# XHSC_HC32F175 register map
Vendor: XHSC Co.Ltd; Series: ARMCM0P; File version: 1.0
CPU: CM0P r0p0, little endian, no MPU, no FPU, 3 interrupt priority bits
Registers are 32-bit, read-write, reset 0x0 unless marked. A register's access mark holds for its fields unless they carry their own. Offsets are from the block's base; [hi:lo] are bit positions; 'fields as' and 'values as' point back to an identical list.

## I2C0 — desc I2C
Base 0x40004800
Same registers: I2C1 0x40009000
0x00 BRREN
  [0] EN
0x04 BRR
  [7:0] BBR
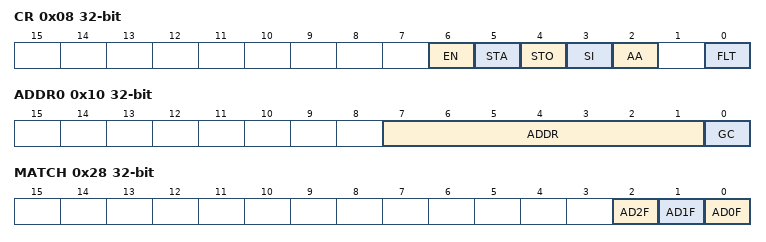
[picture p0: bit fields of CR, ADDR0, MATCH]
0x08 CR
  [6] EN, [5] STA, [4] STO, [3] SI, [2] AA, [0] FLT
0x0C DR
  [7:0] DR
0x10 ADDR0
  [7:1] ADDR, [0] GC
0x14 STAT ro reset 0xF8
  [7:0] STAT
0x20 ADDR1
  [7:0] ADDR
0x24 ADDR2
  [7:0] ADDR
0x28 MATCH ro
  [2] AD2F, [1] AD1F, [0] AD0F

## IWDT
Base 0x40000800
0x80 KR wo
  [15:0] KR rw
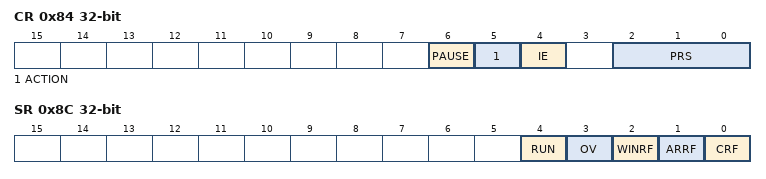
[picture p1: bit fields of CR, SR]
0x84 CR
  [6] PAUSE, [5] ACTION, [4] IE, [2:0] PRS
0x88 ARR reset 0xFFF
  [11:0] ARR
0x8C SR
  [4] RUN ro, [3] OV, [2] WINRF ro, [1] ARRF ro, [0] CRF ro
0x90 WINR reset 0xFFF
  [11:0] WINR

## LPTIM0 — desc LPTIM
Base 0x40005000
Same registers: LPTIM1 0x4000C000
0x00 CNT ro
  [15:0] CNT
0x04 ARR
  [15:0] ARR
0x08 CMP
  [15:0] CMP
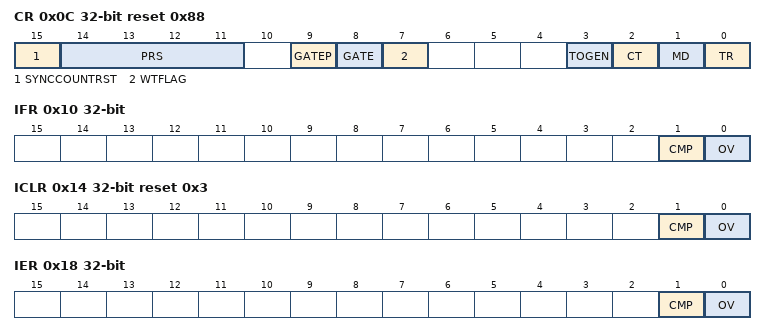
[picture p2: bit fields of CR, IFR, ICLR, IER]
0x0C CR reset 0x88
  [15] SYNCCOUNTRST wo, [14:11] PRS, [9] GATEP, [8] GATE, [7] WTFLAG ro, [3] TOGEN, [2] CT, [1] MD, [0] TR
0x10 IFR ro
  [1] CMP, [0] OV
0x14 ICLR wo reset 0x3
  [1] CMP, [0] OV
0x18 IER
  [1] CMP, [0] OV

## LPUART0 — desc LPUART
Base 0x40003800
Same registers: LPUART1 0x4000B400
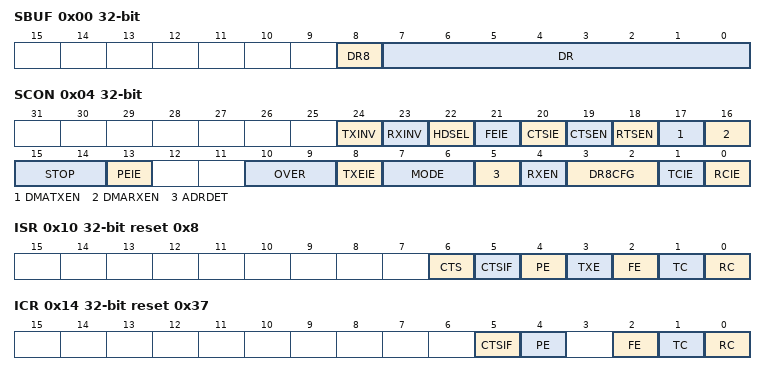
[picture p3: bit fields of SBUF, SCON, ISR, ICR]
0x00 SBUF
  [8] DR8, [7:0] DR
0x04 SCON
  [24] TXINV, [23] RXINV, [22] HDSEL, [21] FEIE, [20] CTSIE, [19] CTSEN, [18] RTSEN, [17] DMATXEN, [16] DMARXEN, [15:14] STOP, [13] PEIE, [10:9] OVER, [8] TXEIE, [7:6] MODE, [5] ADRDET, [4] RXEN, [3:2] DR8CFG, [1] TCIE, [0] RCIE
0x08 SADDR
  [7:0] ADDR
0x0C SADEN
  [7:0] MASK
0x10 ISR ro reset 0x8
  [6] CTS, [5] CTSIF, [4] PE, [3] TXE, [2] FE, [1] TC, [0] RC
0x14 ICR reset 0x37
  [5] CTSIF, [4] PE, [2] FE, [1] TC, [0] RC
0x18 SCNT
  [15:0] SCNT
0x1C BSEL
  [1:0] BSEL
0x20 MODU reset 0x54A
  [11:0] MODU
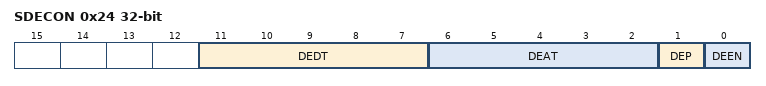
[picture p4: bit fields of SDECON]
0x24 SDECON
  [11:7] DEDT, [6:2] DEAT, [1] DEP, [0] DEEN

## LVD
Base 0x40007400
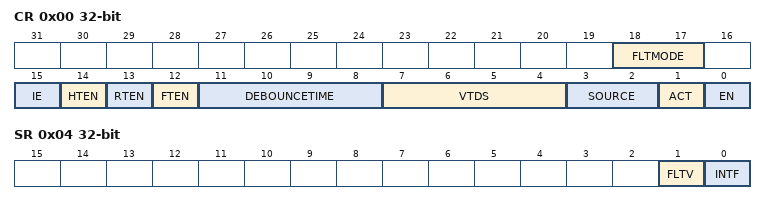
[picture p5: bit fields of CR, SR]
0x00 CR
  [18:17] FLTMODE, [15] IE, [14] HTEN, [13] RTEN, [12] FTEN, [11:8] DEBOUNCETIME, [7:4] VTDS, [3:2] SOURCE, [1] ACT, [0] EN
0x04 SR
  [1] FLTV ro, [0] INTF
0x08 LOCK wo
  [15:0] LOCK

## RTC
Base 0x40001000
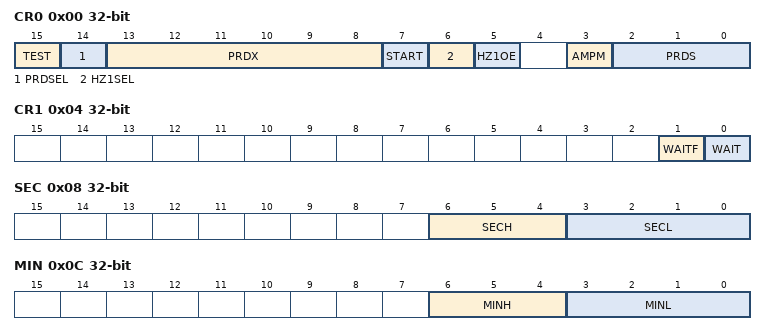
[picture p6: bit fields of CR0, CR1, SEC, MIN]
0x00 CR0
  [15] TEST, [14] PRDSEL, [13:8] PRDX, [7] START, [6] HZ1SEL, [5] HZ1OE, [3] AMPM, [2:0] PRDS
0x04 CR1
  [1] WAITF ro, [0] WAIT
0x08 SEC
  [6:4] SECH, [3:0] SECL
0x0C MIN
  [6:4] MINH, [3:0] MINL
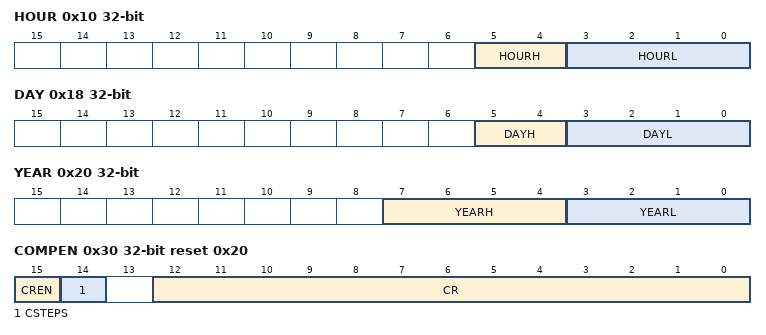
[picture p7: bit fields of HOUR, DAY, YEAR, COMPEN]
0x10 HOUR
  [5:4] HOURH, [3:0] HOURL
0x14 WEEK
  [2:0] WEEK
0x18 DAY
  [5:4] DAYH, [3:0] DAYL
0x1C MON
  [4:0] MON
0x20 YEAR
  [7:4] YEARH, [3:0] YEARL
0x30 COMPEN reset 0x20
  [15] CREN, [14] CSTEPS, [12:0] CR
0x34 HCOMP
  [5:0] PARA
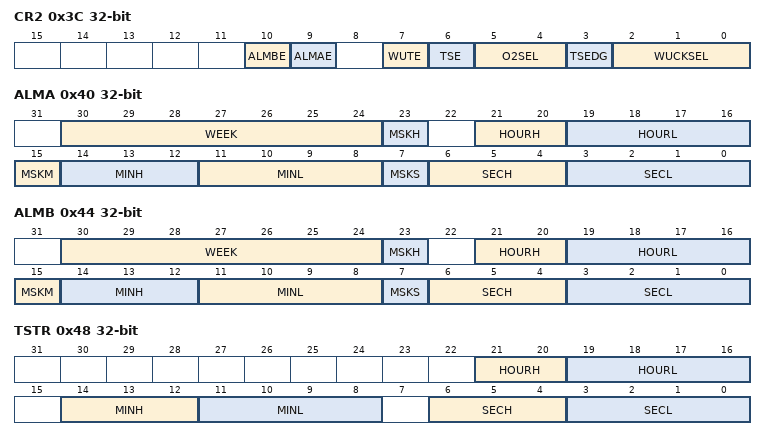
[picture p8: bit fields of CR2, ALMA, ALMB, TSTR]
0x3C CR2
  [10] ALMBE, [9] ALMAE, [7] WUTE, [6] TSE, [5:4] O2SEL, [3] TSEDG, [2:0] WUCKSEL
0x40 ALMA
  [30:24] WEEK, [23] MSKH, [21:20] HOURH, [19:16] HOURL, [15] MSKM, [14:12] MINH, [11:8] MINL, [7] MSKS, [6:4] SECH, [3:0] SECL
0x44 ALMB
  fields as ALMA
0x48 TSTR ro
  [21:20] HOURH, [19:16] HOURL, [14:12] MINH, [11:8] MINL, [6:4] SECH, [3:0] SECL
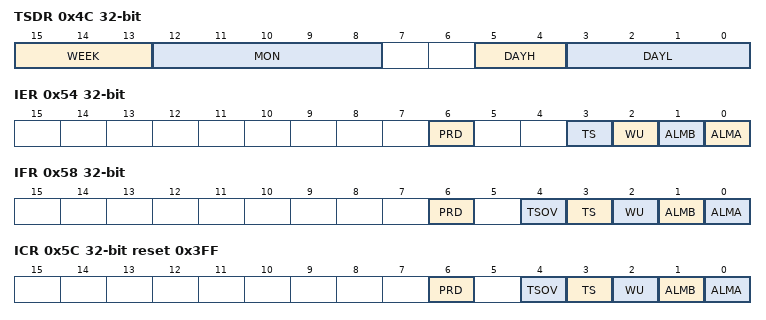
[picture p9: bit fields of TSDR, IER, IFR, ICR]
0x4C TSDR ro
  [15:13] WEEK, [12:8] MON, [5:4] DAYH, [3:0] DAYL
0x50 WUTR reset 0xFFFF
  [15:0] ARR
0x54 IER
  [6] PRD, [3] TS, [2] WU, [1] ALMB, [0] ALMA
0x58 IFR ro
  [6] PRD, [4] TSOV, [3] TS, [2] WU, [1] ALMB, [0] ALMA
0x5C ICR wo reset 0x3FF
  [6] PRD, [4] TSOV, [3] TS, [2] WU, [1] ALMB, [0] ALMA
0x60 WPR wo
  [7:0] WPR

## SPI0 — desc SPI
Base 0x40004000
Same registers: SPI1 0x40008800
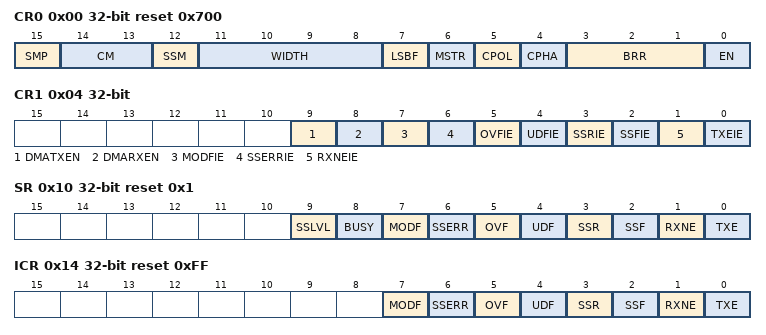
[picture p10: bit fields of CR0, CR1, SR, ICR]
0x00 CR0 reset 0x700
  [15] SMP, [14:13] CM, [12] SSM, [11:8] WIDTH, [7] LSBF, [6] MSTR, [5] CPOL, [4] CPHA, [3:1] BRR, [0] EN
0x04 CR1
  [9] DMATXEN, [8] DMARXEN, [7] MODFIE, [6] SSERRIE, [5] OVFIE, [4] UDFIE, [3] SSRIE, [2] SSFIE, [1] RXNEIE, [0] TXEIE
0x08 HDOE
  [0] HDOE
0x0C SSI reset 0x1
  [0] SSI
0x10 SR ro reset 0x1
  [9] SSLVL, [8] BUSY, [7] MODF, [6] SSERR, [5] OVF, [4] UDF, [3] SSR, [2] SSF, [1] RXNE, [0] TXE
0x14 ICR wo reset 0xFF
  [7] MODF, [6] SSERR, [5] OVF, [4] UDF, [3] SSR, [2] SSF, [1] RXNE, [0] TXE
0x18 DR
  [15:0] DR
